AUTOSAR XML (schema 4-0-3)
standard types defined: UInt32
package /PATAC/MSM/ComponentTypes
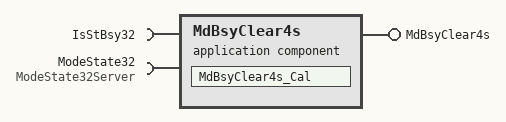
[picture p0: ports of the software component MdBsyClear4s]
  application sw component type MdBsyClear4s
    provide port MdBsyClear4s: server-com-spec{operation=Cal, queue-length=1}, provided-interface=MdBsyClear4s
    require port IsStBsy32: required-com-specs=[IsStBsy32/Clear, IsStBsy32/Get, IsStBsy32/Set], required-interface=IsStBsy32
    require port ModeState32: required-com-specs=[ModeState32Server/Clear, ModeState32Server/Get, ModeState32Server/Set], required-interface=ModeState32Server
    behavior MdBsyClear4s_InternalBehavior
      operation invoked event OIT_MdBsyClear4s_Cal_MdBsyClear4s_Cal: start-on-event=MdBsyClear4s_Cal, operation=MdBsyClear4s.Cal
      runnable MdBsyClear4s_Cal
        sync call SC_IsStBsy32_Clear: operation=IsStBsy32.Clear, timeout=0
        sync call SC_ModeState32_Get: operation=ModeState32.Get, timeout=0
  swc implementation MdBsyClear4s_Implementation: behavior=MdBsyClear4s_InternalBehavior
    code-descriptors:
      code Default: artifact-descriptors=autosar-engineering-object={short-label=Default, category=SWSRC}
package /PATAC/MSM/ModeAdjust/PortInterface
  client server interface IsStBsy32
    operation Clear
      arg ClearBit: type=UInt32, direction=IN, server-argument-impl-policy=USE-ARGUMENT-TYPE
    operation Get
      arg IsStBsy32Bit: type=UInt32, direction=OUT, server-argument-impl-policy=USE-ARGUMENT-TYPE
    operation Set
      arg SetBit: type=UInt32, direction=IN, server-argument-impl-policy=USE-ARGUMENT-TYPE
  client server interface MdBsyClear4s
    operation Cal
  client server interface ModeState32Server
    operation Clear
      arg ClearBit: type=UInt32, direction=IN, server-argument-impl-policy=USE-ARGUMENT-TYPE
    operation Get
      arg MdEn32: type=UInt32, direction=OUT, server-argument-impl-policy=USE-ARGUMENT-TYPE
    operation Set
      arg SetBit: type=UInt32, direction=IN, server-argument-impl-policy=USE-ARGUMENT-TYPE
